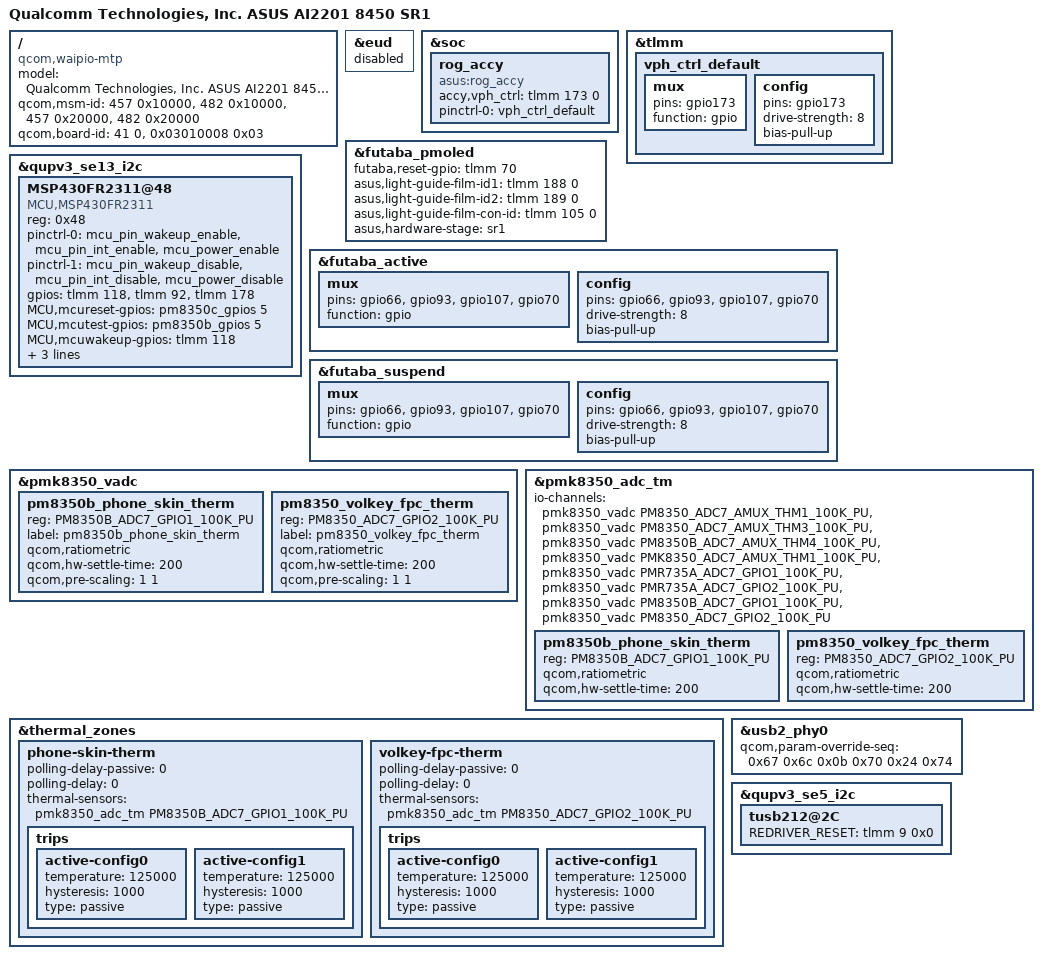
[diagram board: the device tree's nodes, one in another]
/dts-v1/;
/plugin/;


#include "AI2201-8450-PreSR-overlay.dts"
/ {
	model = "Qualcomm Technologies, Inc. ASUS AI2201 8450 SR1";
	compatible = "qcom,waipio-mtp", "qcom,waipio", "qcom,mtp";
	qcom,msm-id = <457 0x10000>, <482 0x10000>, <457 0x20000>, <482 0x20000>;
	qcom,board-id = <41 0>, <0x03010008 0x03>;
};
/*   ====================================
*    overlay for display - start
*    ====================================
*/

/*   ====================================
*    overlay for display - end
*    ====================================
*/

/*   ====================================
*    overlay for touch - start
*    ====================================
*/


/*   ====================================
*    overlay for touch - end
*    ====================================
*/

/*    ====================================
 *    overlay for waipio.dtsi - start
 *    ====================================
 */
&eud {
	status = "disabled";
};
/*    ====================================
 *    overlay for waipio.dtsi - end
 *    ====================================
 */



/*    ====================================
 *    overlay for waipio-mtp.dtsi - start
 *    ====================================
 */

//ASUS BSP Deeo : ROG ACCY driver +++
&soc {
	rog_accy {
		compatible = "asus:rog_accy";

		accy,vph_ctrl = <&tlmm 173 0>;
		pinctrl-names = "vph_ctrl_default";
		pinctrl-0 = <&vph_ctrl_default>;

		status = "okay";
	};
};
//ASUS BSP Deeo : ROG ACCY driver ---

/*    ====================================
 *    overlay for waipio-mtp.dtsi - end
 *    ====================================
 */


/*    ====================================
 *    overlay for waipio-pinctrl.dtsi - start
 *    ====================================
 */

//ASUS BSP Deeo : ROG ACCY driver +++
&tlmm {
	vph_ctrl_default: vph_ctrl_default {
		mux {
			pins = "gpio173";
			function = "gpio";
		};
		config {
			pins = "gpio173";
			drive-strength = <8>;
			bias-pull-up;
		};
	};
};
//ASUS BSP Deeo : ROG ACCY driver ---

/*    ====================================
 *    overlay for waipio-pinctrl.dtsi - end
 *    ====================================
 */

/*    ====================================
 *    overlay for waipio-qupv3.dtsi - start
 *    ====================================
 */

&qupv3_se13_i2c {
	status = "ok";
	MSP430FR2311@48 {
		compatible = "MCU,MSP430FR2311";
		reg = <0x48>;
		//vcc_s4a_1p8-supply = <&pm8150_s4>;
		//vcc_l10a_3p3-supply = <&pm8350c_l11>;
		pinctrl-names = "mcu_active", "mcu_suspend";
		pinctrl-0 = <&mcu_pin_wakeup_enable &mcu_pin_int_enable &mcu_power_enable>;
		pinctrl-1 = <&mcu_pin_wakeup_disable &mcu_pin_int_disable &mcu_power_disable>;
		gpios = <&tlmm 118 0>, <&tlmm 92 0>, <&tlmm 178 0>;

		MCU,mcureset-gpios = <&pm8350c_gpios 5 0x0>;
		MCU,mcutest-gpios = <&pm8350b_gpios 5 0x0>;
		MCU,mcuwakeup-gpios = <&tlmm 118 0x00>;
		MCU,mcuint-gpios = <&tlmm 92 0x00>;
		MCU,power-gpios = <&tlmm 178 0x00>;
		MCU,slave_address = <0x48>;
	};
};

//PMOLED
&futaba_pmoled {
	futaba,reset-gpio = <&tlmm 70 0>;
	// to determine if there is PMOLED on the board
	asus,light-guide-film-id1 = <&tlmm 188 0>;
	asus,light-guide-film-id2 = <&tlmm 189 0>;
	asus,light-guide-film-con-id = <&tlmm 105 0>;
	asus,hardware-stage = "sr1";
};

&futaba_active {
	mux {
		pins = "gpio66", "gpio93", "gpio107", "gpio70";
		function = "gpio";
	};
	config {
		pins = "gpio66", "gpio93", "gpio107", "gpio70";
		drive-strength = <8>;
		bias-pull-up;
	};
};

&futaba_suspend {
	mux {
		pins = "gpio66", "gpio93", "gpio107", "gpio70";
		function = "gpio";
	};
	config {
		pins = "gpio66", "gpio93", "gpio107", "gpio70";
		drive-strength = <8>; //keeping as resume config
		bias-pull-up;
	};
};

/*    ====================================
 *    overlay for waipio-qupv3.dtsi - end
 *    ====================================
 */

/*    ====================================
 *    overlay for waipio-pmic-overlay.dtsi - start
 *    ====================================
 */

&pmk8350_vadc {
	pm8350b_phone_skin_therm {
		reg = <PM8350B_ADC7_GPIO1_100K_PU>;
		label = "pm8350b_phone_skin_therm";
		qcom,ratiometric;
		qcom,hw-settle-time = <200>;
		qcom,pre-scaling = <1 1>;
	};
	pm8350_volkey_fpc_therm {
		reg = <PM8350_ADC7_GPIO2_100K_PU>;
		label = "pm8350_volkey_fpc_therm";
		qcom,ratiometric;
		qcom,hw-settle-time = <200>;
		qcom,pre-scaling = <1 1>;
	};
};

&pmk8350_adc_tm {
	io-channels = <&pmk8350_vadc PM8350_ADC7_AMUX_THM1_100K_PU>,
			<&pmk8350_vadc PM8350_ADC7_AMUX_THM3_100K_PU>,
			<&pmk8350_vadc PM8350B_ADC7_AMUX_THM4_100K_PU>,
			<&pmk8350_vadc PMK8350_ADC7_AMUX_THM1_100K_PU>,
			<&pmk8350_vadc PMR735A_ADC7_GPIO1_100K_PU>,
			<&pmk8350_vadc PMR735A_ADC7_GPIO2_100K_PU>,
			<&pmk8350_vadc PM8350B_ADC7_GPIO1_100K_PU>,
			<&pmk8350_vadc PM8350_ADC7_GPIO2_100K_PU>;

	pm8350b_phone_skin_therm {
		reg = <PM8350B_ADC7_GPIO1_100K_PU>;
		qcom,ratiometric;
		qcom,hw-settle-time = <200>;
	};

	pm8350_volkey_fpc_therm {
		reg = <PM8350_ADC7_GPIO2_100K_PU>;
		qcom,ratiometric;
		qcom,hw-settle-time = <200>;
	};
};

&thermal_zones {
	phone-skin-therm {
		polling-delay-passive = <0>;
		polling-delay = <0>;
		thermal-sensors = <&pmk8350_adc_tm PM8350B_ADC7_GPIO1_100K_PU>;
		trips {
			active-config0 {
				temperature = <125000>;
				hysteresis = <1000>;
				type = "passive";
			};
			active-config1 {
				temperature = <125000>;
				hysteresis = <1000>;
				type = "passive";
			};
		};
	};
	volkey-fpc-therm {
		polling-delay-passive = <0>;
		polling-delay = <0>;
		thermal-sensors = <&pmk8350_adc_tm PM8350_ADC7_GPIO2_100K_PU>;
		trips {
			active-config0 {
				temperature = <125000>;
				hysteresis = <1000>;
				type = "passive";
			};
			active-config1 {
				temperature = <125000>;
				hysteresis = <1000>;
				type = "passive";
			};
		};
	};
};

/*    ====================================
 *    overlay for waipio-pmic-overlay.dtsi - end
 *    ====================================
 */


/*    ====================================
 *    overlay for pm8450.dtsi - start
 *    ====================================
 */

/*    ====================================
 *    overlay for pm8450.dtsi - end
 *    ====================================
 */


/*    ====================================
 *    overlay for waipio-regulators.dtsi - start
 *    ====================================
 */

/*    ====================================
 *    overlay for waipio-regulators.dtsi - end
 *    ====================================
 */



/*    ====================================
 *    overlay for waipio-audio.dtsi - start
 *    ====================================
 */

/*    ====================================
 *    overlay for waipio-audio.dtsi - end
 *    ====================================
 */

/*    ====================================
 *    overlay for waipio-audio-overlay.dtsi - start
 *    ====================================
 */

/*    ====================================
 *    overlay for waipio-audio-overlay.dtsi - end
 *    ====================================
 */


/*    ====================================
 *    overlay for waipio-thermal-overlay.dtsi - start
 *    ====================================
 */

/*    ====================================
 *    overlay for waipio-thermal-overlay.dtsi - end
 *    ====================================
 */


/*    ====================================
 *    overlay for waipio-gpu.dtsi - start
 *    ====================================
 */

/*    ====================================
 *    overlay for waipio-gpu.dtsi - end
 *    ====================================
 */


/*    ====================================
 *    overlay for waipio-usb.dtsi - start
 *    ====================================
 */

&usb2_phy0 {
	qcom,param-override-seq =
		<0x67 0x6c
		 0x0b 0x70
		 0x24 0x74>;
};

&qupv3_se5_i2c {
	tusb212@2C {
		REDRIVER_RESET = <&tlmm 9 0x0>;
	};
};

/*    ====================================
 *    overlay for waipio-usb.dtsi - end
 *    ====================================
 */
